# STM32F103xG register map
File version: 1.0
Registers are 32-bit, read-write, reset 0x0 unless marked. A register's access mark holds for its fields unless they carry their own. Offsets are from the block's base; [hi:lo] are bit positions; {n}, {i} and the like mark numbered series; 'fields as' and 'values as' point back to an identical list.

## FSMC_Bank2_3 — Flexible Static Memory Controller Bank2
Base 0xA0000060
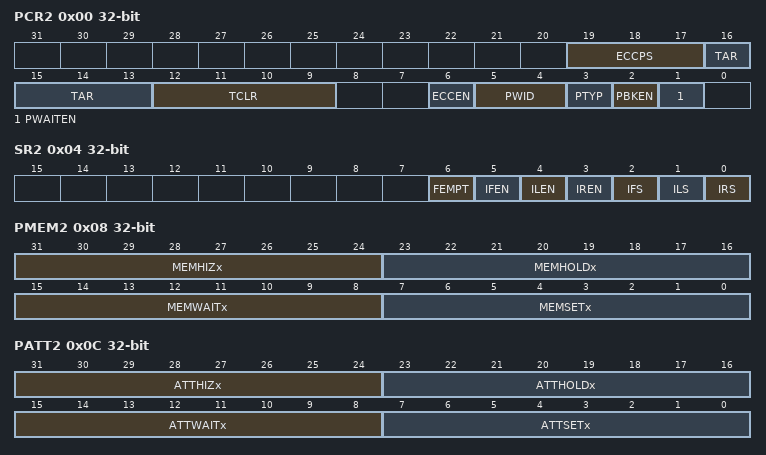
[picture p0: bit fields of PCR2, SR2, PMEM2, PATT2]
0x00 PCR2 — NAND Flash control register 2
  [19:17] ECCPS — ECCPS[1:0] bits (ECC page size)
  [16:13] TAR — TAR[3:0] bits (ALE to RE delay)
  [12:9] TCLR — TCLR[3:0] bits (CLE to RE delay)
  [6] ECCEN — ECC computation logic enable bit
  [5:4] PWID — PWID[1:0] bits (NAND Flash databus width)
  [3] PTYP — Memory type
  [2] PBKEN — PC Card/NAND Flash memory bank enable bit
  [1] PWAITEN — Wait feature enable bit
0x04 SR2 — NAND Flash FIFO status and interrupt register 2
  [6] FEMPT — FIFO empty
  [5] IFEN — Interrupt Falling Edge detection Enable bit
  [4] ILEN — Interrupt Level detection Enable bit
  [3] IREN — Interrupt Rising Edge detection Enable bit
  [2] IFS — Interrupt Falling Edge status
  [1] ILS — Interrupt Level status
  [0] IRS — Interrupt Rising Edge status
0x08 PMEM2 — NAND Flash Common memory space timing register 2
  [31:24] MEMHIZx — MEMHIZx[7:0] bits (Common memory x databus HiZ time)
  [23:16] MEMHOLDx — MEMHOLDx[7:0] bits (Common memory x hold time)
  [15:8] MEMWAITx — MEMWAITx[7:0] bits (Common memory x wait time)
  [7:0] MEMSETx — MEMSETx[7:0] bits (Common memory x setup time)
0x0C PATT2 — NAND Flash Attribute memory space timing register 2
  [31:24] ATTHIZx — ATTHIZx[7:0] bits (Attribute memory x databus HiZ time)
  [23:16] ATTHOLDx — ATTHOLDx[7:0] bits (Attribute memory x hold time)
  [15:8] ATTWAITx — ATTWAITx[7:0] bits (Attribute memory x wait time)
  [7:0] ATTSETx — ATTSETx[7:0] bits (Attribute memory x setup time)
0x14 ECCR2 — NAND Flash ECC result registers 2
  [31:0] ECC2 — ECC result
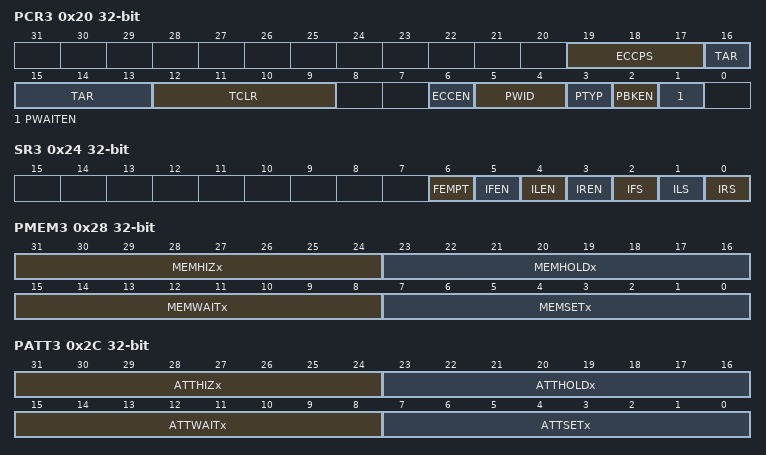
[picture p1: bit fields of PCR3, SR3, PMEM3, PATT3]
0x20 PCR3 — NAND Flash control register 3
  fields as PCR2
0x24 SR3 — NAND Flash FIFO status and interrupt register 3
  fields as SR2
0x28 PMEM3 — NAND Flash Common memory space timing register 3
  fields as PMEM2
0x2C PATT3 — NAND Flash Attribute memory space timing register 3
  fields as PATT2
0x34 ECCR3 — NAND Flash ECC result registers 3
  [31:0] ECC3 — ECC result

## FSMC_Bank1E — Flexible Static Memory Controller Bank1E
Base 0xA0000104
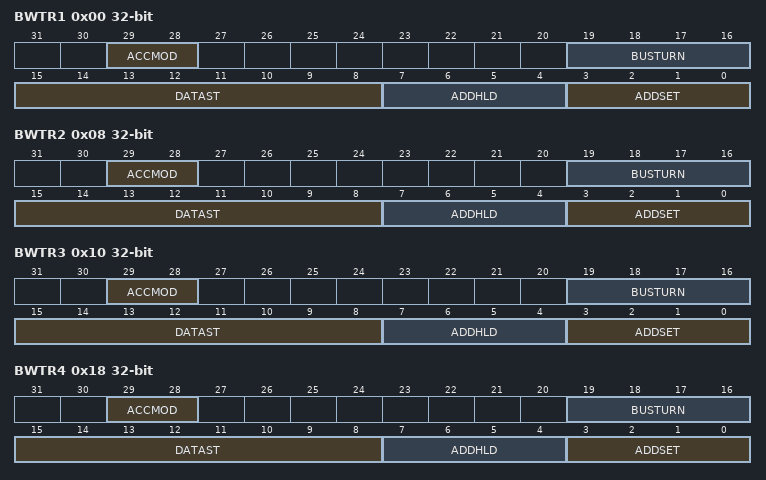
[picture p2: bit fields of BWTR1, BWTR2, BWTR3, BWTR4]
0x00 BWTR1
  [29:28] ACCMOD — ACCMOD[1:0] bits (Access mode)
  [19:16] BUSTURN — BUSTURN[3:0] bits (Bus turnaround phase duration)
  [15:8] DATAST — DATAST [3:0] bits (Data-phase duration)
  [7:4] ADDHLD — ADDHLD[3:0] bits (Address-hold phase duration)
  [3:0] ADDSET — ADDSET[3:0] bits (Address setup phase duration)
0x08 BWTR2
  fields as BWTR1
0x10 BWTR3
  fields as BWTR1
0x18 BWTR4
  fields as BWTR1

## DBGMCU — Debug MCU
Base 0xE0042000
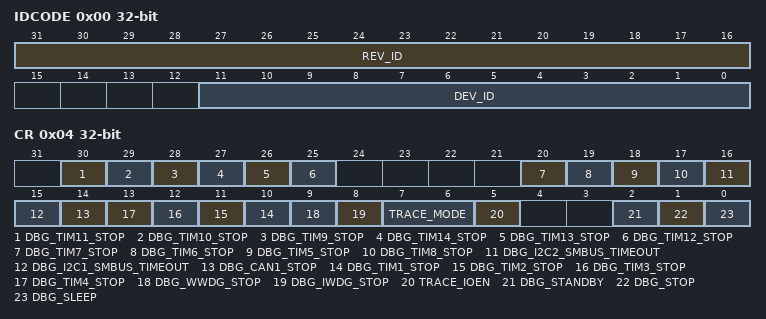
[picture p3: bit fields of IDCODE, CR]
0x00 IDCODE
  [31:16] REV_ID — REV_ID[15:0] bits (Revision Identifier)
  [11:0] DEV_ID — Device Identifier
0x04 CR
  [30] DBG_TIM11_STOP — Debug TIM11 stopped when Core is halted
  [29] DBG_TIM10_STOP — Debug TIM10 stopped when Core is halted
  [28] DBG_TIM9_STOP — Debug TIM9 stopped when Core is halted
  [27] DBG_TIM14_STOP — Debug TIM14 stopped when Core is halted
  [26] DBG_TIM13_STOP — Debug TIM13 stopped when Core is halted
  [25] DBG_TIM12_STOP — Debug TIM12 stopped when Core is halted
  [20] DBG_TIM7_STOP — TIM7 counter stopped when core is halted
  [19] DBG_TIM6_STOP — TIM6 counter stopped when core is halted
  [18] DBG_TIM5_STOP — TIM5 counter stopped when core is halted
  [17] DBG_TIM8_STOP — TIM8 counter stopped when core is halted
  [16] DBG_I2C2_SMBUS_TIMEOUT — SMBUS timeout mode stopped when Core is halted
  [15] DBG_I2C1_SMBUS_TIMEOUT — SMBUS timeout mode stopped when Core is halted
  [14] DBG_CAN1_STOP — Debug CAN1 stopped when Core is halted
  [n+9] DBG_TIM{n}_STOP (n=1..4) — TIM{n} counter stopped when core is halted
  [9] DBG_WWDG_STOP — Debug Window Watchdog stopped when Core is halted
  [8] DBG_IWDG_STOP — Debug Independent Watchdog stopped when Core is halted
  [7:6] TRACE_MODE — TRACE_MODE[1:0] bits (Trace Pin Assignment Control)
  [5] TRACE_IOEN — Trace Pin Assignment Control
  [2] DBG_STANDBY — Debug Standby mode
  [1] DBG_STOP — Debug Stop Mode
  [0] DBG_SLEEP — Debug Sleep Mode
